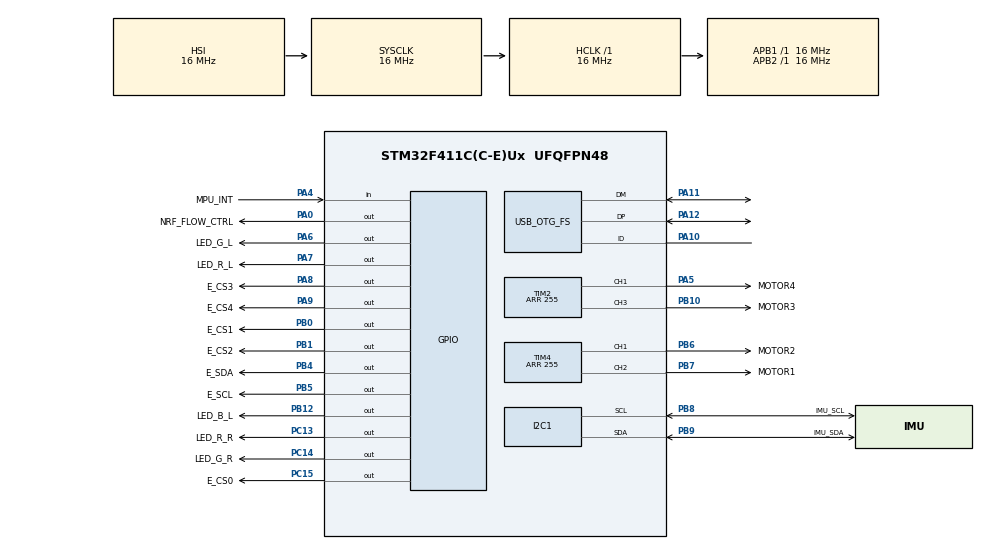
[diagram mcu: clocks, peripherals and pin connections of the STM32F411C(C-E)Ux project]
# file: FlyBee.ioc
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Dma.I2C1_RX.0.Direction=DMA_PERIPH_TO_MEMORY
Dma.I2C1_RX.0.FIFOMode=DMA_FIFOMODE_ENABLE
Dma.I2C1_RX.0.FIFOThreshold=DMA_FIFO_THRESHOLD_FULL
Dma.I2C1_RX.0.Instance=DMA1_Stream0
Dma.I2C1_RX.0.MemBurst=DMA_MBURST_SINGLE
Dma.I2C1_RX.0.MemDataAlignment=DMA_MDATAALIGN_BYTE
Dma.I2C1_RX.0.MemInc=DMA_MINC_ENABLE
Dma.I2C1_RX.0.Mode=DMA_NORMAL
Dma.I2C1_RX.0.PeriphBurst=DMA_PBURST_SINGLE
Dma.I2C1_RX.0.PeriphDataAlignment=DMA_PDATAALIGN_BYTE
Dma.I2C1_RX.0.PeriphInc=DMA_PINC_DISABLE
Dma.I2C1_RX.0.Priority=DMA_PRIORITY_LOW
Dma.I2C1_TX.1.Direction=DMA_MEMORY_TO_PERIPH
Dma.I2C1_TX.1.FIFOMode=DMA_FIFOMODE_ENABLE
Dma.I2C1_TX.1.FIFOThreshold=DMA_FIFO_THRESHOLD_FULL
Dma.I2C1_TX.1.Instance=DMA1_Stream1
Dma.I2C1_TX.1.MemBurst=DMA_MBURST_SINGLE
Dma.I2C1_TX.1.MemDataAlignment=DMA_MDATAALIGN_BYTE
Dma.I2C1_TX.1.MemInc=DMA_MINC_ENABLE
Dma.I2C1_TX.1.Mode=DMA_NORMAL
Dma.I2C1_TX.1.PeriphBurst=DMA_PBURST_SINGLE
Dma.I2C1_TX.1.PeriphDataAlignment=DMA_PDATAALIGN_BYTE
Dma.I2C1_TX.1.PeriphInc=DMA_PINC_DISABLE
Dma.I2C1_TX.1.Priority=DMA_PRIORITY_LOW
Dma.Request0=I2C1_RX
Dma.Request1=I2C1_TX
FREERTOS.Tasks01=defaultTask,24,128,StartDefaultTask,Default,NULL,Dynamic,NULL,NULL
FREERTOS.configENABLE_FPU=1
Mcu.Family=STM32F4
Mcu.Name=STM32F411C(C-E)Ux
Mcu.Package=UFQFPN48
NVIC.DMA1_Stream0_IRQn=true\:5\:0\:false\:false\:true\:true\:false\:true\:true
NVIC.DMA1_Stream1_IRQn=true\:5\:0\:false\:false\:true\:true\:false\:true\:true
NVIC.I2C1_ER_IRQn=true\:5\:0\:false\:false\:true\:true\:true\:true\:true
NVIC.I2C1_EV_IRQn=true\:5\:0\:false\:false\:true\:true\:true\:true\:true
NVIC.PriorityGroup=NVIC_PRIORITYGROUP_4
PA0-WKUP.GPIO_Label=NRF_FLOW_CTRL
PA0-WKUP.Signal=GPIO_Output
PA10.Mode=OTG/Dual_Role_Device
PA10.Signal=USB_OTG_FS_ID
PA11.Mode=OTG/Dual_Role_Device
PA11.Signal=USB_OTG_FS_DM
PA12.Mode=OTG/Dual_Role_Device
PA12.Signal=USB_OTG_FS_DP
PA13.Signal=SYS_JTMS-SWDIO
PA14.Signal=SYS_JTCK-SWCLK
PA15.GPIO_Label=E_TX
PA15.Signal=USART1_TX
PA2.GPIO_Label=ToNRF_Tx
PA2.Signal=USART2_TX
PA3.GPIO_Label=ToNRF_Rx
PA3.Signal=USART2_RX
PA4.GPIO_Label=MPU_INT
PA4.Signal=GPIO_Input
PA5.GPIO_Label=MOTOR4
PA5.Signal=S_TIM2_CH1_ETR
PA6.GPIO_Label=LED_G_L
PA6.Signal=GPIO_Output
PA7.GPIO_Label=LED_R_L
PA7.Signal=GPIO_Output
PA8.GPIO_Label=E_CS3
PA8.Signal=GPIO_Output
PA9.GPIO_Label=E_CS4
PA9.Signal=GPIO_Output
PB0.GPIO_Label=E_CS1
PB0.Signal=GPIO_Output
PB1.GPIO_Label=E_CS2
PB1.Signal=GPIO_Output
PB10.GPIO_Label=MOTOR3
PB10.Signal=S_TIM2_CH3
PB12.GPIO_Label=LED_B_L
PB12.Signal=GPIO_Output
PB13.GPIO_Label=E_SCK
PB13.Signal=SPI2_SCK
PB14.GPIO_Label=E_MISO
PB14.Signal=SPI2_MISO
PB15.GPIO_Label=E_MOSI
PB15.Signal=SPI2_MOSI
PB3.GPIO_Label=E_RX
PB3.Signal=USART1_RX
PB4.GPIO_Label=E_SDA 
PB4.Signal=GPIO_Output
PB5.GPIO_Label=E_SCL
PB5.Signal=GPIO_Output
PB6.GPIO_Label=MOTOR2
PB6.Signal=S_TIM4_CH1
PB7.GPIO_Label=MOTOR1
PB7.Signal=S_TIM4_CH2
PB8.GPIO_Label=IMU_SCL
PB8.Mode=I2C
PB8.Signal=I2C1_SCL
PB9.GPIO_Label=IMU_SDA
PB9.Mode=I2C
PB9.Signal=I2C1_SDA
PC13-ANTI_TAMP.GPIO_Label=LED_R_R
PC13-ANTI_TAMP.Signal=GPIO_Output
PC14-OSC32_IN.GPIO_Label=LED_G_R
PC14-OSC32_IN.Signal=GPIO_Output
PC15-OSC32_OUT.GPIO_Label=E_CS0
PC15-OSC32_OUT.Signal=GPIO_Output
PH0\ -\ OSC_IN.Mode=HSE-External-Oscillator
PH0\ -\ OSC_IN.Signal=RCC_OSC_IN
PH1\ -\ OSC_OUT.Mode=HSE-External-Oscillator
PH1\ -\ OSC_OUT.Signal=RCC_OSC_OUT
ProjectManager.HeapSize=0x200
ProjectManager.StackSize=0x400
ProjectManager.TargetToolchain=MDK-ARM V5
RCC.48MHZClocksFreq_Value=48000000
RCC.AHBFreq_Value=16000000
RCC.APB1Freq_Value=16000000
RCC.APB2Freq_Value=16000000
RCC.CortexFreq_Value=16000000
RCC.HSE_VALUE=25000000
RCC.HSI_VALUE=16000000
RCC.LSE_VALUE=32768
RCC.PLLM=15
RCC.PLLN=144
RCC.PLLQ=5
RCC.SYSCLKFreq_VALUE=16000000
RCC.VCOOutputFreq_Value=240000000
SH.S_TIM2_CH1_ETR.0=TIM2_CH1,PWM Generation1 CH1
SH.S_TIM2_CH3.0=TIM2_CH3,PWM Generation3 CH3
SH.S_TIM4_CH1.0=TIM4_CH1,PWM Generation1 CH1
SH.S_TIM4_CH2.0=TIM4_CH2,PWM Generation2 CH2
TIM2.Channel-PWM\ Generation1\ CH1=TIM_CHANNEL_1
TIM2.Channel-PWM\ Generation3\ CH3=TIM_CHANNEL_3
TIM2.Period=255
TIM4.Channel-PWM\ Generation1\ CH1=TIM_CHANNEL_1
TIM4.Channel-PWM\ Generation2\ CH2=TIM_CHANNEL_2
TIM4.Period=255
VP_CRC_VS_CRC.Mode=CRC_Activate
VP_FREERTOS_VS_CMSIS_V2.Mode=CMSIS_V2
board=custom

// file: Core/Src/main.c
/* USER CODE BEGIN Header */
/**
  ******************************************************************************
  * @file           : main.c
  * @brief          : Main program body
  ******************************************************************************
  * @attention
  *
  * Copyright (c) 2023 STMicroelectronics.
  * All rights reserved.
  *
  * This software is licensed under terms that can be found in the LICENSE file
  * in the root directory of this software component.
  * If no LICENSE file comes with this software, it is provided AS-IS.
  *
  ******************************************************************************
  */
/* USER CODE END Header */
#include "main.h"
#include "cmsis_os.h"
#include "crc.h"
#include "dma.h"
#include "i2c.h"
#include "tim.h"
#include "usb_otg.h"
#include "gpio.h"

void SystemClock_Config(void);
void MX_FREERTOS_Init(void);

int main(void)
{

  /* MCU Configuration--------------------------------------------------------*/

  /* Reset of all peripherals, Initializes the Flash interface and the Systick. */
  HAL_Init();

  /* Configure the system clock */
  SystemClock_Config();

  /* Initialize all configured peripherals */
  MX_GPIO_Init();
  MX_DMA_Init();
  MX_TIM2_Init();
  MX_TIM4_Init();
  MX_I2C1_Init();
  MX_USB_OTG_FS_USB_Init();
  MX_CRC_Init();

  /* Init scheduler */
  osKernelInitialize();  /* Call init function for freertos objects (in freertos.c) */
  MX_FREERTOS_Init();

  /* Start scheduler */
  osKernelStart();
  /* We should never get here as control is now taken by the scheduler */
  /* Infinite loop */
  while (1)
  {

  }
}

void SystemClock_Config(void)
{
  RCC_OscInitTypeDef RCC_OscInitStruct = {0};
  RCC_ClkInitTypeDef RCC_ClkInitStruct = {0};

  /** Configure the main internal regulator output voltage
  */
  __HAL_RCC_PWR_CLK_ENABLE();
  __HAL_PWR_VOLTAGESCALING_CONFIG(PWR_REGULATOR_VOLTAGE_SCALE1);

  /** Initializes the RCC Oscillators according to the specified parameters
  * in the RCC_OscInitTypeDef structure.
  */
  RCC_OscInitStruct.OscillatorType = RCC_OSCILLATORTYPE_HSI|RCC_OSCILLATORTYPE_HSE;
  RCC_OscInitStruct.HSEState = RCC_HSE_ON;
  RCC_OscInitStruct.HSIState = RCC_HSI_ON;
  RCC_OscInitStruct.HSICalibrationValue = RCC_HSICALIBRATION_DEFAULT;
  RCC_OscInitStruct.PLL.PLLState = RCC_PLL_ON;
  RCC_OscInitStruct.PLL.PLLSource = RCC_PLLSOURCE_HSE;
  RCC_OscInitStruct.PLL.PLLM = 15;
  RCC_OscInitStruct.PLL.PLLN = 144;
  RCC_OscInitStruct.PLL.PLLP = RCC_PLLP_DIV2;
  RCC_OscInitStruct.PLL.PLLQ = 5;
  if (HAL_RCC_OscConfig(&RCC_OscInitStruct) != HAL_OK)
  {
    Error_Handler();
  }

  /** Initializes the CPU, AHB and APB buses clocks
  */
  RCC_ClkInitStruct.ClockType = RCC_CLOCKTYPE_HCLK|RCC_CLOCKTYPE_SYSCLK
                              |RCC_CLOCKTYPE_PCLK1|RCC_CLOCKTYPE_PCLK2;
  RCC_ClkInitStruct.SYSCLKSource = RCC_SYSCLKSOURCE_HSI;
  RCC_ClkInitStruct.AHBCLKDivider = RCC_SYSCLK_DIV1;
  RCC_ClkInitStruct.APB1CLKDivider = RCC_HCLK_DIV1;
  RCC_ClkInitStruct.APB2CLKDivider = RCC_HCLK_DIV1;

  if (HAL_RCC_ClockConfig(&RCC_ClkInitStruct, FLASH_LATENCY_0) != HAL_OK)
  {
    Error_Handler();
  }
}

void Error_Handler(void)
{
  __disable_irq();
  while (1)
  {
  }
}

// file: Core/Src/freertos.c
/* USER CODE BEGIN Header */
/**
  ******************************************************************************
  * File Name          : freertos.c
  * Description        : Code for freertos applications
  ******************************************************************************
  * @attention
  *
  * Copyright (c) 2023 STMicroelectronics.
  * All rights reserved.
  *
  * This software is licensed under terms that can be found in the LICENSE file
  * in the root directory of this software component.
  * If no LICENSE file comes with this software, it is provided AS-IS.
  *
  ******************************************************************************
  */
/* USER CODE END Header */

#include "FreeRTOS.h"
#include "task.h"
#include "main.h"
#include "cmsis_os.h"

/* USER CODE BEGIN Variables */
osThreadId_t powerManagementTaskHandle;
const osThreadAttr_t powerManagementTask_attributes = {
  .name = "powerManagement",
  .stack_size = 128 * 4,
  .priority = (osPriority_t) osPriorityNormal,
};
/* USER CODE END Variables */
/* Definitions for defaultTask */
osThreadId_t defaultTaskHandle;
const osThreadAttr_t defaultTask_attributes = {
  .name = "defaultTask",
  .stack_size = 128 * 4,
  .priority = (osPriority_t) osPriorityNormal,
};

/* USER CODE BEGIN FunctionPrototypes */
void powerManagementTask(void *arguement);

/* USER CODE END FunctionPrototypes */

void StartDefaultTask(void *argument);

void MX_FREERTOS_Init(void); /* (MISRA C 2004 rule 8.1) */

void MX_FREERTOS_Init(void) {

  /* Create the thread(s) */
  /* creation of defaultTask */
  defaultTaskHandle = osThreadNew(StartDefaultTask, NULL, &defaultTask_attributes);

  /* USER CODE BEGIN RTOS_THREADS */
  powerManagementTaskHandle = osThreadNew(powerManagementTask, NULL, &powerManagementTask_attributes);
  /* USER CODE END RTOS_THREADS */

}

void StartDefaultTask(void *argument)
{
  for(;;)
  {
    osDelay(1);
  }
}
